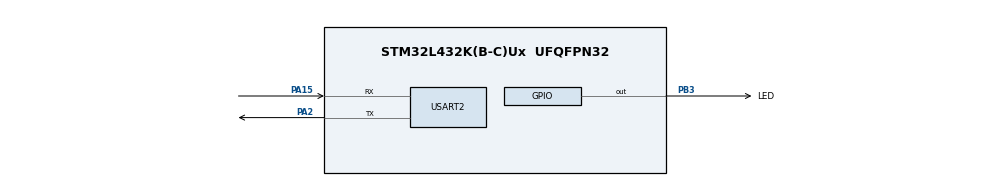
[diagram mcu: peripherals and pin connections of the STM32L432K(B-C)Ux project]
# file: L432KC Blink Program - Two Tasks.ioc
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FREERTOS.Tasks01=defaultTask,24,128,StartDefaultTask,Default,NULL,Dynamic,NULL,NULL;LEDOn,24,128,StartLEDOn,Default,NULL,Dynamic,NULL,NULL;LEDOff,24,128,StartLEDOff,Default,NULL,Dynamic,NULL,NULL
FREERTOS.configUSE_NEWLIB_REENTRANT=1
Mcu.Family=STM32L4
Mcu.Name=STM32L432K(B-C)Ux
Mcu.Package=UFQFPN32
NVIC.PriorityGroup=NVIC_PRIORITYGROUP_4
NVIC.TIM1_UP_TIM16_IRQn=true\:15\:0\:false\:false\:true\:false\:false\:true\:true
NVIC.TimeBase=TIM1_UP_TIM16_IRQn
NVIC.TimeBaseIP=TIM1
PA13\ (JTMS-SWDIO).Mode=Serial_Wire
PA13\ (JTMS-SWDIO).Signal=SYS_JTMS-SWDIO
PA14\ (JTCK-SWCLK).Mode=Serial_Wire
PA14\ (JTCK-SWCLK).Signal=SYS_JTCK-SWCLK
PA15\ (JTDI).Mode=Asynchronous
PA15\ (JTDI).Signal=USART2_RX
PA2.Mode=Asynchronous
PA2.Signal=USART2_TX
PB3\ (JTDO-TRACESWO).GPIO_Label=LED
PB3\ (JTDO-TRACESWO).Signal=GPIO_Output
ProjectManager.HeapSize=0x200
ProjectManager.StackSize=0x400
ProjectManager.TargetToolchain=STM32CubeIDE
RCC.HSE_VALUE=8000000
RCC.HSI48_VALUE=48000000
RCC.HSI_VALUE=16000000
RCC.LSE_VALUE=32768
RCC.MSI_VALUE=4000000
RCC.VCOOutputFreq_Value=32000000
USART2.VirtualMode-Asynchronous=VM_ASYNC
VP_FREERTOS_VS_CMSIS_V2.Mode=CMSIS_V2
VP_SYS_VS_tim1.Mode=TIM1
board=custom

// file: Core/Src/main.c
/* USER CODE BEGIN Header */
/**
  ******************************************************************************
  * @file           : main.c
  * @brief          : Main program body
  ******************************************************************************
  * @attention
  *
  * Copyright (c) 2026 STMicroelectronics.
  * All rights reserved.
  *
  * This software is licensed under terms that can be found in the LICENSE file
  * in the root directory of this software component.
  * If no LICENSE file comes with this software, it is provided AS-IS.
  *
  ******************************************************************************
  */
/* USER CODE END Header */
#include "main.h"
#include "cmsis_os.h"

/* USER CODE BEGIN Includes */

#include <stdio.h>

/* USER CODE END Includes */

UART_HandleTypeDef huart2;

/* Definitions for defaultTask */
osThreadId_t defaultTaskHandle;
const osThreadAttr_t defaultTask_attributes = {
  .name = "defaultTask",
  .stack_size = 128 * 4,
  .priority = (osPriority_t) osPriorityNormal,
};
/* Definitions for LEDOn */
osThreadId_t LEDOnHandle;
const osThreadAttr_t LEDOn_attributes = {
  .name = "LEDOn",
  .stack_size = 128 * 4,
  .priority = (osPriority_t) osPriorityNormal,
};
/* Definitions for LEDOff */
osThreadId_t LEDOffHandle;
const osThreadAttr_t LEDOff_attributes = {
  .name = "LEDOff",
  .stack_size = 128 * 4,
  .priority = (osPriority_t) osPriorityNormal,
};

void SystemClock_Config(void);
static void MX_GPIO_Init(void);
static void MX_USART2_UART_Init(void);
void StartDefaultTask(void *argument);
void StartLEDOn(void *argument);
void StartLEDOff(void *argument);

int main(void)
{

  /* USER CODE BEGIN 1 */

static uint8_t serial_string[51] = "";

  /* USER CODE END 1 */

  /* MCU Configuration--------------------------------------------------------*/

  /* Reset of all peripherals, Initializes the Flash interface and the Systick. */
  HAL_Init();

  /* Configure the system clock */
  SystemClock_Config();

  /* Initialize all configured peripherals */
  MX_GPIO_Init();
  MX_USART2_UART_Init();
  /* USER CODE BEGIN 2 */

  sprintf((char *)serial_string, "Hello from STM32L4 via UART.\r\n");
  HAL_UART_Transmit(&huart2,serial_string, 51, 10);

  /* USER CODE END 2 */

  /* Init scheduler */
  osKernelInitialize();

  /* Create the thread(s) */
  /* creation of defaultTask */
  defaultTaskHandle = osThreadNew(StartDefaultTask, NULL, &defaultTask_attributes);

  /* creation of LEDOn */
  LEDOnHandle = osThreadNew(StartLEDOn, NULL, &LEDOn_attributes);

  /* creation of LEDOff */
  LEDOffHandle = osThreadNew(StartLEDOff, NULL, &LEDOff_attributes);

  /* Start scheduler */
  osKernelStart();

  /* We should never get here as control is now taken by the scheduler */

  /* Infinite loop */
  while (1)
  {

  }
}

void SystemClock_Config(void)
{
  RCC_OscInitTypeDef RCC_OscInitStruct = {0};
  RCC_ClkInitTypeDef RCC_ClkInitStruct = {0};

  /** Configure the main internal regulator output voltage
  */
  if (HAL_PWREx_ControlVoltageScaling(PWR_REGULATOR_VOLTAGE_SCALE1) != HAL_OK)
  {
    Error_Handler();
  }

  /** Initializes the RCC Oscillators according to the specified parameters
  * in the RCC_OscInitTypeDef structure.
  */
  RCC_OscInitStruct.OscillatorType = RCC_OSCILLATORTYPE_MSI;
  RCC_OscInitStruct.MSIState = RCC_MSI_ON;
  RCC_OscInitStruct.MSICalibrationValue = 0;
  RCC_OscInitStruct.MSIClockRange = RCC_MSIRANGE_6;
  RCC_OscInitStruct.PLL.PLLState = RCC_PLL_NONE;
  if (HAL_RCC_OscConfig(&RCC_OscInitStruct) != HAL_OK)
  {
    Error_Handler();
  }

  /** Initializes the CPU, AHB and APB buses clocks
  */
  RCC_ClkInitStruct.ClockType = RCC_CLOCKTYPE_HCLK|RCC_CLOCKTYPE_SYSCLK
                              |RCC_CLOCKTYPE_PCLK1|RCC_CLOCKTYPE_PCLK2;
  RCC_ClkInitStruct.SYSCLKSource = RCC_SYSCLKSOURCE_MSI;
  RCC_ClkInitStruct.AHBCLKDivider = RCC_SYSCLK_DIV1;
  RCC_ClkInitStruct.APB1CLKDivider = RCC_HCLK_DIV1;
  RCC_ClkInitStruct.APB2CLKDivider = RCC_HCLK_DIV1;

  if (HAL_RCC_ClockConfig(&RCC_ClkInitStruct, FLASH_LATENCY_0) != HAL_OK)
  {
    Error_Handler();
  }
}

static void MX_USART2_UART_Init(void)
{

  huart2.Instance = USART2;
  huart2.Init.BaudRate = 115200;
  huart2.Init.WordLength = UART_WORDLENGTH_8B;
  huart2.Init.StopBits = UART_STOPBITS_1;
  huart2.Init.Parity = UART_PARITY_NONE;
  huart2.Init.Mode = UART_MODE_TX_RX;
  huart2.Init.HwFlowCtl = UART_HWCONTROL_NONE;
  huart2.Init.OverSampling = UART_OVERSAMPLING_16;
  huart2.Init.OneBitSampling = UART_ONE_BIT_SAMPLE_DISABLE;
  huart2.AdvancedInit.AdvFeatureInit = UART_ADVFEATURE_NO_INIT;
  if (HAL_UART_Init(&huart2) != HAL_OK)
  {
    Error_Handler();
  }

}

static void MX_GPIO_Init(void)
{
  GPIO_InitTypeDef GPIO_InitStruct = {0};

  /* GPIO Ports Clock Enable */
  __HAL_RCC_GPIOA_CLK_ENABLE();
  __HAL_RCC_GPIOB_CLK_ENABLE();

  /*Configure GPIO pin Output Level */
  HAL_GPIO_WritePin(LED_GPIO_Port, LED_Pin, GPIO_PIN_RESET);

  /*Configure GPIO pin : LED_Pin */
  GPIO_InitStruct.Pin = LED_Pin;
  GPIO_InitStruct.Mode = GPIO_MODE_OUTPUT_PP;
  GPIO_InitStruct.Pull = GPIO_NOPULL;
  GPIO_InitStruct.Speed = GPIO_SPEED_FREQ_LOW;
  HAL_GPIO_Init(LED_GPIO_Port, &GPIO_InitStruct);

}

void StartDefaultTask(void *argument)
{
  for(;;)
  {
    osDelay(1);
  }
}

void StartLEDOn(void *argument)
{
  /* USER CODE BEGIN StartLEDOn */
  /* Infinite loop */
  for(;;)
  {
	HAL_GPIO_WritePin(LED_GPIO_Port, LED_Pin, GPIO_PIN_SET);
    osDelay(1000);
  }
  /* USER CODE END StartLEDOn */
}

void StartLEDOff(void *argument)
{
  /* USER CODE BEGIN StartLEDOff */
  /* Infinite loop */
  for(;;)
  {
	HAL_GPIO_WritePin(LED_GPIO_Port, LED_Pin, GPIO_PIN_RESET);
    osDelay(500);
  }
  /* USER CODE END StartLEDOff */
}

void HAL_TIM_PeriodElapsedCallback(TIM_HandleTypeDef *htim)
{
  if (htim->Instance == TIM1)
  {
    HAL_IncTick();
  }
}

void Error_Handler(void)
{
  __disable_irq();
  while (1)
  {
  }
}
